VERSION ""

NS_ :

BS_:

BU_: AMS_Impeller FCU DMI Logger MCU RCU AMS
VAL_TABLE_ MCU_Control_Drive_Mode 3 "Torque Vectoring" 2 "Slip Control" 1 "Torque Limiting" 0 "Throttle Curve" ;
VAL_TABLE_ MCU_Inverter_State_VT 3 "Error" 2 "Active" 1 "Ready" 0 "Init" ;
VAL_TABLE_ Fuse_Set_Enable 2 "Enable E-Fuse" 1 "Disable E-Fuse" 0 "No Change" ;
VAL_TABLE_ Fuse_Fault 1 "E-Fuse no fault" 0 "E-Fuse has fault" ;
VAL_TABLE_ Fuse_Enable 1 "E-Fuse enabled" 0 "E-Fuse disabled" ;

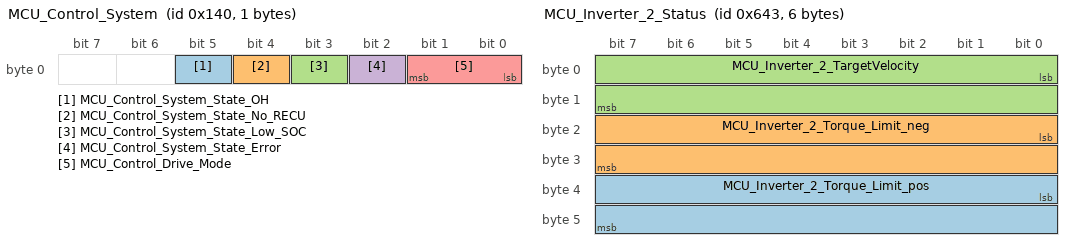
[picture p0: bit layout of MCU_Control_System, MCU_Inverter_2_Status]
BO_ 320 MCU_Control_System: 1 MCU
 SG_ MCU_Control_System_State_OH : 5|1@1+ (1,0) [0|1] "" Vector__XXX
 SG_ MCU_Control_System_State_No_RECU : 4|1@1+ (1,0) [0|1] "" Vector__XXX
 SG_ MCU_Control_System_State_Low_SOC : 3|1@1+ (1,0) [0|1] "" Vector__XXX
 SG_ MCU_Control_System_State_Error : 2|1@1+ (1,0) [0|1] "" Vector__XXX
 SG_ MCU_Control_Drive_Mode : 0|2@1+ (1,0) [0|3] "" Vector__XXX

BO_ 1603 MCU_Inverter_2_Status: 6 MCU
 SG_ MCU_Inverter_2_Torque_Limit_pos : 32|16@1+ (0.1,0) [0|1000] "%" Vector__XXX
 SG_ MCU_Inverter_2_Torque_Limit_neg : 16|16@1+ (0.1,0) [0|1000] "%" Vector__XXX
 SG_ MCU_Inverter_2_TargetVelocity : 0|16@1+ (1,0) [0|65535] "rpm" Vector__XXX

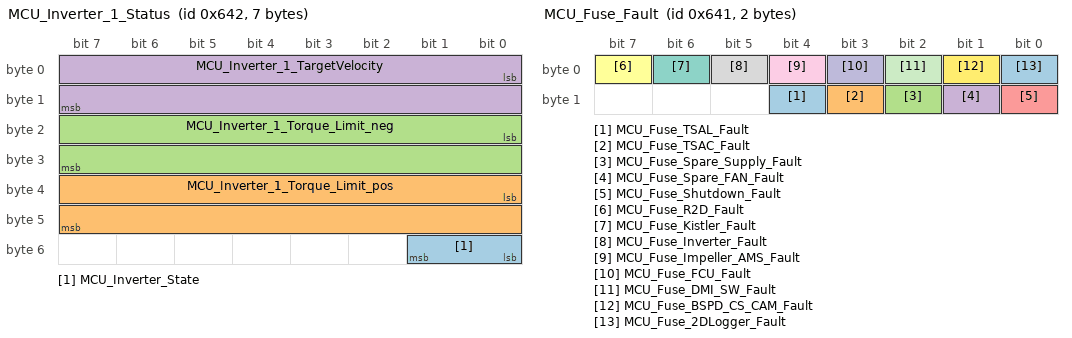
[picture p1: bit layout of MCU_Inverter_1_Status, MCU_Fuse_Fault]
BO_ 1602 MCU_Inverter_1_Status: 7 MCU
 SG_ MCU_Inverter_State : 48|2@1+ (1,0) [0|3] "" Vector__XXX
 SG_ MCU_Inverter_1_Torque_Limit_pos : 32|16@1+ (0.1,0) [0|1000] "%" Vector__XXX
 SG_ MCU_Inverter_1_Torque_Limit_neg : 16|16@1+ (0.1,0) [0|1000] "%" Vector__XXX
 SG_ MCU_Inverter_1_TargetVelocity : 0|16@1+ (1,0) [0|65535] "rpm" Vector__XXX

BO_ 1601 MCU_Fuse_Fault: 2 MCU
 SG_ MCU_Fuse_TSAL_Fault : 12|1@1+ (1,0) [0|1] "" Vector__XXX
 SG_ MCU_Fuse_TSAC_Fault : 11|1@1+ (1,0) [0|1] "" Vector__XXX
 SG_ MCU_Fuse_Spare_Supply_Fault : 10|1@1+ (1,0) [0|1] "" Vector__XXX
 SG_ MCU_Fuse_Spare_FAN_Fault : 9|1@1+ (1,0) [0|1] "" Vector__XXX
 SG_ MCU_Fuse_Shutdown_Fault : 8|1@1+ (1,0) [0|1] "" Vector__XXX
 SG_ MCU_Fuse_R2D_Fault : 7|1@1+ (1,0) [0|1] "" Vector__XXX
 SG_ MCU_Fuse_Kistler_Fault : 6|1@1+ (1,0) [0|1] "" Vector__XXX
 SG_ MCU_Fuse_Inverter_Fault : 5|1@1+ (1,0) [0|1] "" Vector__XXX
 SG_ MCU_Fuse_Impeller_AMS_Fault : 4|1@1+ (1,0) [0|1] "" Vector__XXX
 SG_ MCU_Fuse_FCU_Fault : 3|1@1+ (1,0) [0|1] "" Vector__XXX
 SG_ MCU_Fuse_DMI_SW_Fault : 2|1@1+ (1,0) [0|1] "" Vector__XXX
 SG_ MCU_Fuse_BSPD_CS_CAM_Fault : 1|1@1+ (1,0) [0|1] "" Vector__XXX
 SG_ MCU_Fuse_2DLogger_Fault : 0|1@1+ (1,0) [0|1] "" Vector__XXX

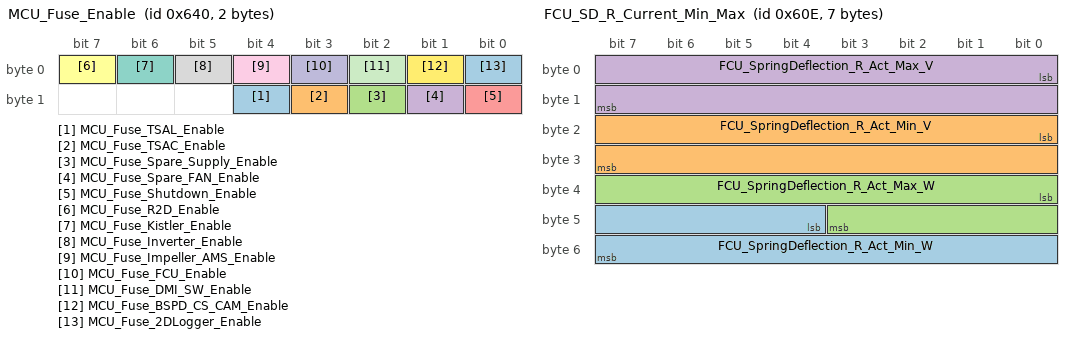
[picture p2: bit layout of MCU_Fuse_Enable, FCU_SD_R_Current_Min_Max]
BO_ 1600 MCU_Fuse_Enable: 2 MCU
 SG_ MCU_Fuse_TSAL_Enable : 12|1@1+ (1,0) [0|1] "" Vector__XXX
 SG_ MCU_Fuse_TSAC_Enable : 11|1@1+ (1,0) [0|1] "" Vector__XXX
 SG_ MCU_Fuse_Spare_Supply_Enable : 10|1@1+ (1,0) [0|1] "" Vector__XXX
 SG_ MCU_Fuse_Spare_FAN_Enable : 9|1@1+ (1,0) [0|1] "" Vector__XXX
 SG_ MCU_Fuse_Shutdown_Enable : 8|1@1+ (1,0) [0|1] "" Vector__XXX
 SG_ MCU_Fuse_R2D_Enable : 7|1@1+ (1,0) [0|1] "" Vector__XXX
 SG_ MCU_Fuse_Kistler_Enable : 6|1@1+ (1,0) [0|1] "" Vector__XXX
 SG_ MCU_Fuse_Inverter_Enable : 5|1@1+ (1,0) [0|1] "" Vector__XXX
 SG_ MCU_Fuse_Impeller_AMS_Enable : 4|1@1+ (1,0) [0|1] "" Vector__XXX
 SG_ MCU_Fuse_FCU_Enable : 3|1@1+ (1,0) [0|1] "" Vector__XXX
 SG_ MCU_Fuse_DMI_SW_Enable : 2|1@1+ (1,0) [0|1] "" Vector__XXX
 SG_ MCU_Fuse_BSPD_CS_CAM_Enable : 1|1@1+ (1,0) [0|1] "" Vector__XXX
 SG_ MCU_Fuse_2DLogger_Enable : 0|1@1+ (1,0) [0|1] "" Vector__XXX

BO_ 1550 FCU_SD_R_Current_Min_Max: 7 FCU
 SG_ FCU_SpringDeflection_R_Act_Min_W : 44|12@1+ (0.02,0) [0|81.9] "" Vector__XXX
 SG_ FCU_SpringDeflection_R_Act_Min_V : 16|16@1+ (0.001,0) [0|5] "V" Vector__XXX
 SG_ FCU_SpringDeflection_R_Act_Max_W : 32|12@1+ (0.02,0) [0|81.9] "" Vector__XXX
 SG_ FCU_SpringDeflection_R_Act_Max_V : 0|16@1+ (0.001,0) [0|5] "V" Vector__XXX

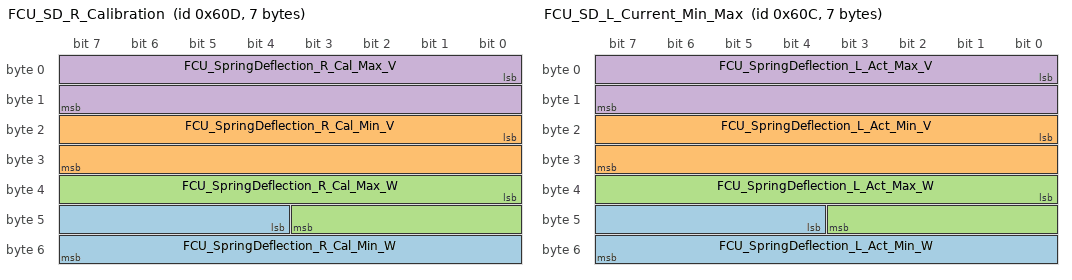
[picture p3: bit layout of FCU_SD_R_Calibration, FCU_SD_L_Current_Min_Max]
BO_ 1549 FCU_SD_R_Calibration: 7 Logger
 SG_ FCU_SpringDeflection_R_Cal_Min_W : 44|12@1+ (0.02,0) [0|81.9] ""  FCU
 SG_ FCU_SpringDeflection_R_Cal_Min_V : 16|16@1+ (0.001,0) [0|5] "V"  FCU
 SG_ FCU_SpringDeflection_R_Cal_Max_W : 32|12@1+ (0.02,0) [0|81.9] ""  FCU
 SG_ FCU_SpringDeflection_R_Cal_Max_V : 0|16@1+ (0.001,0) [0|5] "V"  FCU

BO_ 1548 FCU_SD_L_Current_Min_Max: 7 FCU
 SG_ FCU_SpringDeflection_L_Act_Min_W : 44|12@1+ (0.02,0) [0|81.9] "" Vector__XXX
 SG_ FCU_SpringDeflection_L_Act_Min_V : 16|16@1+ (0.001,0) [0|5] "V" Vector__XXX
 SG_ FCU_SpringDeflection_L_Act_Max_W : 32|12@1+ (0.02,0) [0|81.9] "" Vector__XXX
 SG_ FCU_SpringDeflection_L_Act_Max_V : 0|16@1+ (0.001,0) [0|5] "V" Vector__XXX

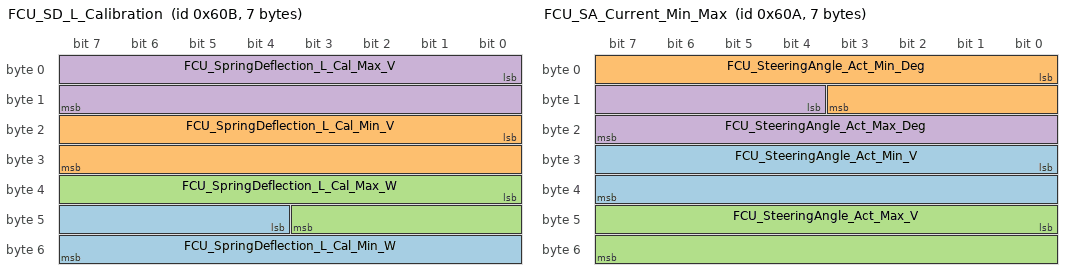
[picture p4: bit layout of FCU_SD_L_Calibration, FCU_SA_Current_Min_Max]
BO_ 1547 FCU_SD_L_Calibration: 7 Logger
 SG_ FCU_SpringDeflection_L_Cal_Min_W : 44|12@1+ (0.02,0) [0|81.9] ""  FCU
 SG_ FCU_SpringDeflection_L_Cal_Min_V : 16|16@1+ (0.001,0) [0|5] "V"  FCU
 SG_ FCU_SpringDeflection_L_Cal_Max_W : 32|12@1+ (0.02,0) [0|81.9] ""  FCU
 SG_ FCU_SpringDeflection_L_Cal_Max_V : 0|16@1+ (0.001,0) [0|5] "V"  FCU

BO_ 1546 FCU_SA_Current_Min_Max: 7 FCU
 SG_ FCU_SteeringAngle_Act_Min_V : 24|16@1+ (0.001,0) [0|5] "V" Vector__XXX
 SG_ FCU_SteeringAngle_Act_Min_Deg : 0|12@1- (0.15,0) [-307.2|307.05] "" Vector__XXX
 SG_ FCU_SteeringAngle_Act_Max_V : 40|16@1+ (0.001,0) [0|5] "V" Vector__XXX
 SG_ FCU_SteeringAngle_Act_Max_Deg : 12|12@1- (0.15,0) [-307.2|307.05] "" Vector__XXX

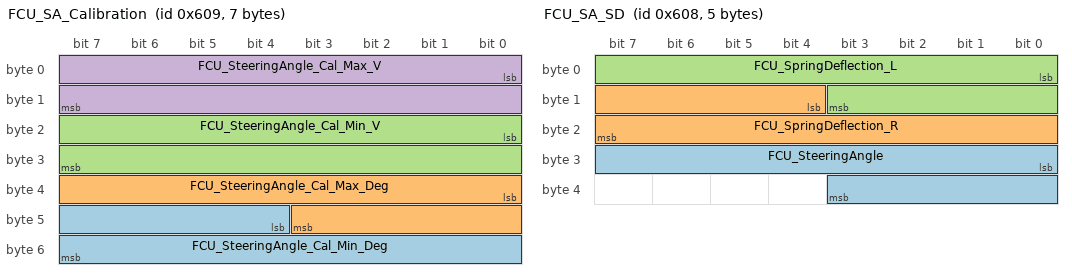
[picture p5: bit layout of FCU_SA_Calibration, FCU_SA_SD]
BO_ 1545 FCU_SA_Calibration: 7 Logger
 SG_ FCU_SteeringAngle_Cal_Min_Deg : 44|12@1- (0.15,0) [-307.2|307.05] ""  FCU
 SG_ FCU_SteeringAngle_Cal_Max_Deg : 32|12@1- (0.15,0) [-307.2|307.05] ""  FCU
 SG_ FCU_SteeringAngle_Cal_Min_V : 16|16@1+ (0.001,0) [0|5] "V"  FCU
 SG_ FCU_SteeringAngle_Cal_Max_V : 0|16@1+ (0.001,0) [0|5] "V"  FCU

BO_ 1544 FCU_SA_SD: 5 FCU
 SG_ FCU_SteeringAngle : 24|12@1- (0.15,0) [-307.2|307.05] "" Vector__XXX
 SG_ FCU_SpringDeflection_R : 12|12@1+ (0.02,0) [0|81.9] "" Vector__XXX
 SG_ FCU_SpringDeflection_L : 0|12@1+ (0.02,0) [0|81.9] "" Vector__XXX

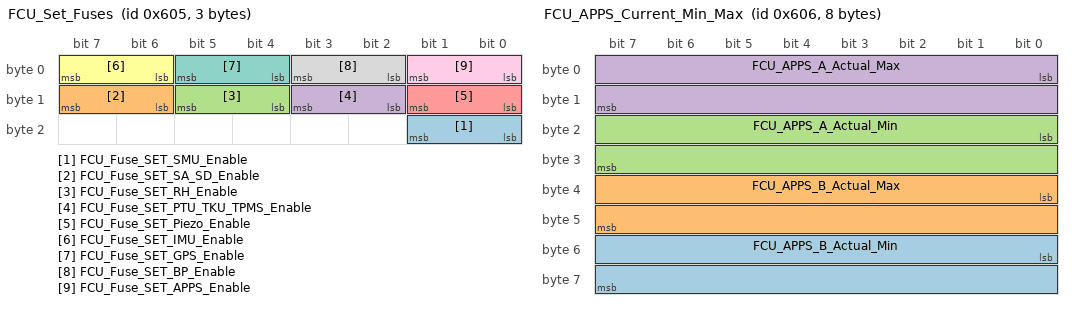
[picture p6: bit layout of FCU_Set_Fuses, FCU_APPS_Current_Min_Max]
BO_ 1541 FCU_Set_Fuses: 3 FCU
 SG_ FCU_Fuse_SET_SMU_Enable : 16|2@1+ (1,-1) [-1|1] "" Vector__XXX
 SG_ FCU_Fuse_SET_SA_SD_Enable : 14|2@1+ (1,-1) [-1|1] "" Vector__XXX
 SG_ FCU_Fuse_SET_RH_Enable : 12|2@1+ (1,-1) [-1|1] "" Vector__XXX
 SG_ FCU_Fuse_SET_PTU_TKU_TPMS_Enable : 10|2@1+ (1,-1) [-1|1] "" Vector__XXX
 SG_ FCU_Fuse_SET_Piezo_Enable : 8|2@1+ (1,-1) [-1|1] "" Vector__XXX
 SG_ FCU_Fuse_SET_IMU_Enable : 6|2@1+ (1,-1) [-1|1] "" Vector__XXX
 SG_ FCU_Fuse_SET_GPS_Enable : 4|2@1+ (1,-1) [-1|1] "" Vector__XXX
 SG_ FCU_Fuse_SET_BP_Enable : 2|2@1+ (1,-1) [-1|1] "" Vector__XXX
 SG_ FCU_Fuse_SET_APPS_Enable : 0|2@1+ (1,-1) [-1|1] "" Vector__XXX

BO_ 1542 FCU_APPS_Current_Min_Max: 8 FCU
 SG_ FCU_APPS_B_Actual_Min : 48|16@1+ (0.001,0) [0|5] "V" Vector__XXX
 SG_ FCU_APPS_B_Actual_Max : 32|16@1+ (0.001,0) [0|5] "V" Vector__XXX
 SG_ FCU_APPS_A_Actual_Min : 16|16@1+ (0.001,0) [0|5] "V" Vector__XXX
 SG_ FCU_APPS_A_Actual_Max : 0|16@1+ (0.001,0) [0|5] "V" Vector__XXX

BO_ 1540 FCU_State: 1 FCU
 SG_ FCU_Alive : 0|8@1+ (1,0) [0|255] "" Vector__XXX

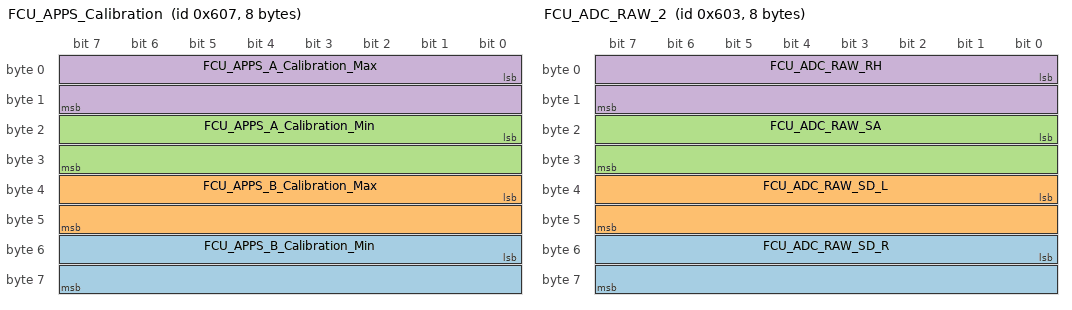
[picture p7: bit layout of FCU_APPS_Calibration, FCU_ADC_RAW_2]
BO_ 1543 FCU_APPS_Calibration: 8 Logger
 SG_ FCU_APPS_B_Calibration_Min : 48|16@1+ (0.001,0) [0|5] "V"  FCU
 SG_ FCU_APPS_B_Calibration_Max : 32|16@1+ (0.001,0) [0|5] "V"  FCU
 SG_ FCU_APPS_A_Calibration_Min : 16|16@1+ (0.001,0) [0|5] "V"  FCU
 SG_ FCU_APPS_A_Calibration_Max : 0|16@1+ (0.001,0) [0|5] "V"  FCU

BO_ 257 FCU_BP: 4 FCU
 SG_ FCU_BP_R : 16|12@1+ (0.1,0) [0|200] "bar" Vector__XXX
 SG_ FCU_BP_F : 0|12@1+ (0.1,0) [0|200] "bar" Vector__XXX

BO_ 256 FCU_APPS: 4 FCU
 SG_ FCU_APPS_B : 16|10@1+ (0.1,0) [0|100] "%" Vector__XXX
 SG_ FCU_APPS_A : 0|10@1+ (0.1,0) [0|100] "%" Vector__XXX

BO_ 1539 FCU_ADC_RAW_2: 8 FCU
 SG_ FCU_ADC_RAW_SD_R : 48|16@1+ (0.001,0) [0|5] "V" Vector__XXX
 SG_ FCU_ADC_RAW_SD_L : 32|16@1+ (0.001,0) [0|5] "V" Vector__XXX
 SG_ FCU_ADC_RAW_SA : 16|16@1+ (0.001,0) [0|5] "V" Vector__XXX
 SG_ FCU_ADC_RAW_RH : 0|16@1+ (0.001,0) [0|5] "V" Vector__XXX

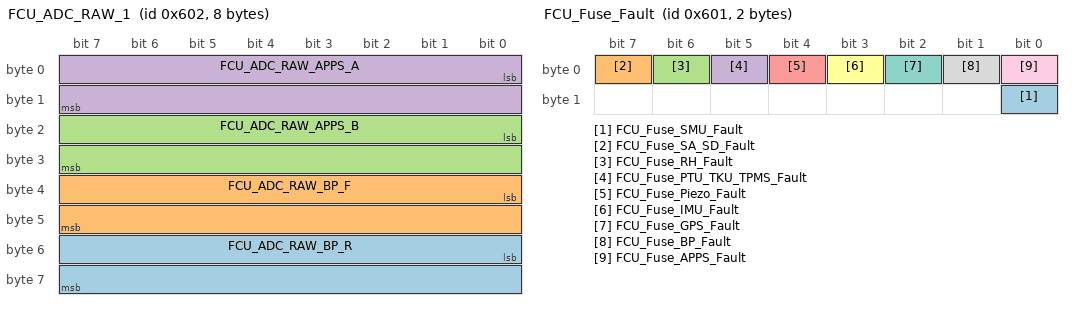
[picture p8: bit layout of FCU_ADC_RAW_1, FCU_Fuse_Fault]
BO_ 1538 FCU_ADC_RAW_1: 8 FCU
 SG_ FCU_ADC_RAW_BP_R : 48|16@1+ (0.001,0) [0|5] "V" Vector__XXX
 SG_ FCU_ADC_RAW_BP_F : 32|16@1+ (0.001,0) [0|5] "V" Vector__XXX
 SG_ FCU_ADC_RAW_APPS_B : 16|16@1+ (0.001,0) [0|5] "V" Vector__XXX
 SG_ FCU_ADC_RAW_APPS_A : 0|16@1+ (0.001,0) [0|5] "V" Vector__XXX

BO_ 1537 FCU_Fuse_Fault: 2 FCU
 SG_ FCU_Fuse_SMU_Fault : 8|1@1+ (1,0) [0|1] "" Vector__XXX
 SG_ FCU_Fuse_SA_SD_Fault : 7|1@1+ (1,0) [0|1] "" Vector__XXX
 SG_ FCU_Fuse_RH_Fault : 6|1@1+ (1,0) [0|1] "" Vector__XXX
 SG_ FCU_Fuse_PTU_TKU_TPMS_Fault : 5|1@1+ (1,0) [0|1] "" Vector__XXX
 SG_ FCU_Fuse_Piezo_Fault : 4|1@1+ (1,0) [0|1] "" Vector__XXX
 SG_ FCU_Fuse_IMU_Fault : 3|1@1+ (1,0) [0|1] "" Vector__XXX
 SG_ FCU_Fuse_GPS_Fault : 2|1@1+ (1,0) [0|1] "" Vector__XXX
 SG_ FCU_Fuse_BP_Fault : 1|1@1+ (1,0) [0|1] "" Vector__XXX
 SG_ FCU_Fuse_APPS_Fault : 0|1@1+ (1,0) [0|1] "" Vector__XXX

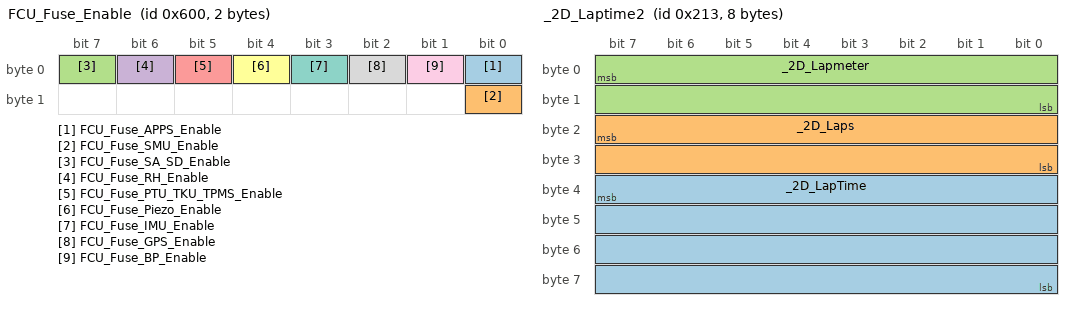
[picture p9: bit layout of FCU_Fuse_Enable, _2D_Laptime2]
BO_ 1536 FCU_Fuse_Enable: 2 FCU
 SG_ FCU_Fuse_APPS_Enable : 0|1@1+ (1,0) [0|1] "" Vector__XXX
 SG_ FCU_Fuse_SMU_Enable : 8|1@1+ (1,0) [0|1] "" Vector__XXX
 SG_ FCU_Fuse_SA_SD_Enable : 7|1@1+ (1,0) [0|1] "" Vector__XXX
 SG_ FCU_Fuse_RH_Enable : 6|1@1+ (1,0) [0|1] "" Vector__XXX
 SG_ FCU_Fuse_PTU_TKU_TPMS_Enable : 5|1@1+ (1,0) [0|1] "" Vector__XXX
 SG_ FCU_Fuse_Piezo_Enable : 4|1@1+ (1,0) [0|1] "" Vector__XXX
 SG_ FCU_Fuse_IMU_Enable : 3|1@1+ (1,0) [0|1] "" Vector__XXX
 SG_ FCU_Fuse_GPS_Enable : 2|1@1+ (1,0) [0|1] "" Vector__XXX
 SG_ FCU_Fuse_BP_Enable : 1|1@1+ (1,0) [0|1] "" Vector__XXX

BO_ 531 _2D_Laptime2: 8 Logger
 SG_ _2D_LapTime : 39|32@0+ (0.001,0) [0|4294967.295] "s" Vector__XXX
 SG_ _2D_Laps : 23|16@0+ (1,0) [0|65535] "#" Vector__XXX
 SG_ _2D_Lapmeter : 7|16@0+ (0.5,0) [0|32767.5] "m" Vector__XXX

BO_ 514 _2D_Laptime1: 4 Logger
 SG_ _2D_deltaToBest : 23|16@0- (0.001,0) [-32.768|32.767] "s" Vector__XXX
 SG_ _2D_BestLap : 7|16@0+ (0.001,0) [0|65.535] "s" Vector__XXX

CM_ SG_ 320 MCU_Control_System_State_OH "Overheat";
CM_ SG_ 320 MCU_Control_System_State_Error "Overheat";
CM_ SG_ 320 MCU_Control_Drive_Mode "Overheat";
CM_ SG_ 1550 FCU_SpringDeflection_R_Act_Min_V "Displays the current set max value for APPS";
CM_ SG_ 1550 FCU_SpringDeflection_R_Act_Max_V "Displays the current set max value for APPS";
CM_ SG_ 1549 FCU_SpringDeflection_R_Cal_Min_V "Displays the current set max value for APPS";
CM_ SG_ 1549 FCU_SpringDeflection_R_Cal_Max_V "Displays the current set max value for APPS";
CM_ SG_ 1548 FCU_SpringDeflection_L_Act_Min_V "Displays the current set max value for APPS";
CM_ SG_ 1548 FCU_SpringDeflection_L_Act_Max_V "Displays the current set max value for APPS";
CM_ SG_ 1547 FCU_SpringDeflection_L_Cal_Min_V "Displays the current set max value for APPS";
CM_ SG_ 1547 FCU_SpringDeflection_L_Cal_Max_V "Displays the current set max value for APPS";
CM_ SG_ 1546 FCU_SteeringAngle_Act_Min_V "Displays the current set max value for APPS";
CM_ SG_ 1546 FCU_SteeringAngle_Act_Max_V "Displays the current set max value for APPS";
CM_ SG_ 1545 FCU_SteeringAngle_Cal_Min_V "Displays the current set max value for APPS";
CM_ SG_ 1545 FCU_SteeringAngle_Cal_Max_V "Displays the current set max value for APPS";
CM_ BO_ 1542 "Currently active min and max values";
CM_ SG_ 1542 FCU_APPS_B_Actual_Min "Displays the current set min value for APPS";
CM_ SG_ 1542 FCU_APPS_B_Actual_Max "Displays the current set max value for APPS";
CM_ SG_ 1542 FCU_APPS_A_Actual_Min "Displays the current set min value for APPS";
CM_ SG_ 1542 FCU_APPS_A_Actual_Max "Displays the current set max value for APPS";
BA_DEF_ SG_  "GenSigStartValue" FLOAT 0 100000000000;
BA_DEF_ SG_  "GenSigSendType" ENUM  "Cyclic","OnWrite","OnWriteWithRepetition","OnChange","OnChangeWithRepetition","IfActive","IfActiveWithRepetition","NoSigSendType","NotUsed","NotUsed","NotUsed","NotUsed","NotUsed";
BA_DEF_ BO_  "GenMsgILSupport" ENUM  "No","Yes";
BA_DEF_ BO_  "GenMsgSendType2" ENUM  "Zyklisch","Ereignisgesteuert","dummy","Auf Anfrage";
BA_DEF_ BO_  "GenMsgFastOnStart" INT 10 500;
BA_DEF_ BO_  "GenMsgCycleTimeActive" INT 1 100;
BA_DEF_ BO_  "VFrameFormat" ENUM  "StandardCAN","ExtendedCAN","reserved","reserved","reserved","reserved","reserved","reserved","reserved","reserved","reserved","reserved","reserved","reserved","StandardCAN_FD","ExtendedCAN_FD";
BA_DEF_ BO_  "GenMsgSendType" ENUM  "Cyclic","NotUsed","NotUsed","NotUsed","NotUsed","NotUsed","NotUsed","IfActive","NoMsgSendType","NotUsed","vector_leerstring";
BA_DEF_ BO_  "GenMsgCycleTime" INT 0 50000;
BA_DEF_  "BusType" STRING ;
BA_DEF_DEF_  "GenSigStartValue" 0;
BA_DEF_DEF_  "GenSigSendType" "Cyclic";
BA_DEF_DEF_  "GenMsgILSupport" "Yes";
BA_DEF_DEF_  "GenMsgSendType2" "Zyklisch";
BA_DEF_DEF_  "GenMsgFastOnStart" 10;
BA_DEF_DEF_  "GenMsgCycleTimeActive" 10;
BA_DEF_DEF_  "VFrameFormat" "ExtendedCAN_FD";
BA_DEF_DEF_  "GenMsgSendType" "NoMsgSendType";
BA_DEF_DEF_  "GenMsgCycleTime" 0;
BA_DEF_DEF_  "BusType" "CAN";
BA_ "VFrameFormat" BO_ 320 0;
BA_ "VFrameFormat" BO_ 1603 0;
BA_ "VFrameFormat" BO_ 1602 0;
BA_ "VFrameFormat" BO_ 1601 0;
BA_ "VFrameFormat" BO_ 1600 0;
BA_ "VFrameFormat" BO_ 1550 0;
BA_ "GenMsgCycleTime" BO_ 1550 1000;
BA_ "GenMsgSendType2" BO_ 1549 1;
BA_ "VFrameFormat" BO_ 1549 0;
BA_ "GenMsgSendType" BO_ 1549 1;
BA_ "VFrameFormat" BO_ 1548 0;
BA_ "GenMsgCycleTime" BO_ 1548 1000;
BA_ "VFrameFormat" BO_ 1547 0;
BA_ "VFrameFormat" BO_ 1546 0;
BA_ "GenMsgCycleTime" BO_ 1546 1000;
BA_ "GenMsgSendType2" BO_ 1545 1;
BA_ "VFrameFormat" BO_ 1545 0;
BA_ "GenMsgSendType" BO_ 1545 1;
BA_ "VFrameFormat" BO_ 1544 0;
BA_ "VFrameFormat" BO_ 1541 0;
BA_ "VFrameFormat" BO_ 1542 0;
BA_ "GenMsgCycleTime" BO_ 1542 1000;
BA_ "VFrameFormat" BO_ 1540 0;
BA_ "GenMsgSendType2" BO_ 1543 1;
BA_ "VFrameFormat" BO_ 1543 0;
BA_ "GenMsgSendType" BO_ 1543 1;
BA_ "VFrameFormat" BO_ 257 0;
BA_ "GenMsgSendType" BO_ 257 0;
BA_ "GenMsgCycleTime" BO_ 257 10;
BA_ "VFrameFormat" BO_ 256 0;
BA_ "GenMsgCycleTime" BO_ 256 10;
BA_ "VFrameFormat" BO_ 1539 0;
BA_ "VFrameFormat" BO_ 1538 0;
BA_ "VFrameFormat" BO_ 1537 0;
BA_ "VFrameFormat" BO_ 1536 0;
BA_ "VFrameFormat" BO_ 531 0;
BA_ "VFrameFormat" BO_ 514 0;
BA_ "GenSigStartValue" SG_ 1541 FCU_Fuse_SET_SMU_Enable 1;
BA_ "GenSigStartValue" SG_ 1541 FCU_Fuse_SET_SA_SD_Enable 1;
BA_ "GenSigStartValue" SG_ 1541 FCU_Fuse_SET_RH_Enable 1;
BA_ "GenSigStartValue" SG_ 1541 FCU_Fuse_SET_PTU_TKU_TPMS_Enable 1;
BA_ "GenSigStartValue" SG_ 1541 FCU_Fuse_SET_Piezo_Enable 1;
BA_ "GenSigStartValue" SG_ 1541 FCU_Fuse_SET_IMU_Enable 1;
BA_ "GenSigStartValue" SG_ 1541 FCU_Fuse_SET_GPS_Enable 1;
BA_ "GenSigStartValue" SG_ 1541 FCU_Fuse_SET_BP_Enable 1;
BA_ "GenSigStartValue" SG_ 1541 FCU_Fuse_SET_APPS_Enable 1;
VAL_ 320 MCU_Control_Drive_Mode 3 "Torque Vectoring" 2 "Slip Control" 1 "Torque Limiting" 0 "Throttle Curve" ;
VAL_ 1602 MCU_Inverter_State 3 "Error" 2 "Active" 1 "Ready" 0 "Init" ;
VAL_ 1601 MCU_Fuse_TSAL_Fault 1 "E-Fuse no fault" 0 "E-Fuse has fault" ;
VAL_ 1601 MCU_Fuse_TSAC_Fault 1 "E-Fuse no fault" 0 "E-Fuse has fault" ;
VAL_ 1601 MCU_Fuse_Spare_Supply_Fault 1 "E-Fuse no fault" 0 "E-Fuse has fault" ;
VAL_ 1601 MCU_Fuse_Spare_FAN_Fault 1 "E-Fuse no fault" 0 "E-Fuse has fault" ;
VAL_ 1601 MCU_Fuse_Shutdown_Fault 1 "E-Fuse no fault" 0 "E-Fuse has fault" ;
VAL_ 1601 MCU_Fuse_R2D_Fault 1 "E-Fuse no fault" 0 "E-Fuse has fault" ;
VAL_ 1601 MCU_Fuse_Kistler_Fault 1 "E-Fuse no fault" 0 "E-Fuse has fault" ;
VAL_ 1601 MCU_Fuse_Inverter_Fault 1 "E-Fuse no fault" 0 "E-Fuse has fault" ;
VAL_ 1601 MCU_Fuse_Impeller_AMS_Fault 1 "E-Fuse no fault" 0 "E-Fuse has fault" ;
VAL_ 1601 MCU_Fuse_FCU_Fault 1 "E-Fuse no fault" 0 "E-Fuse has fault" ;
VAL_ 1601 MCU_Fuse_DMI_SW_Fault 1 "E-Fuse no fault" 0 "E-Fuse has fault" ;
VAL_ 1601 MCU_Fuse_BSPD_CS_CAM_Fault 1 "E-Fuse no fault" 0 "E-Fuse has fault" ;
VAL_ 1601 MCU_Fuse_2DLogger_Fault 1 "E-Fuse no fault" 0 "E-Fuse has fault" ;
VAL_ 1600 MCU_Fuse_TSAL_Enable 1 "E-Fuse enabled" 0 "E-Fuse disabled" ;
VAL_ 1600 MCU_Fuse_TSAC_Enable 1 "E-Fuse enabled" 0 "E-Fuse disabled" ;
VAL_ 1600 MCU_Fuse_Spare_Supply_Enable 1 "E-Fuse enabled" 0 "E-Fuse disabled" ;
VAL_ 1600 MCU_Fuse_Spare_FAN_Enable 1 "E-Fuse enabled" 0 "E-Fuse disabled" ;
VAL_ 1600 MCU_Fuse_Shutdown_Enable 1 "E-Fuse enabled" 0 "E-Fuse disabled" ;
VAL_ 1600 MCU_Fuse_R2D_Enable 1 "E-Fuse enabled" 0 "E-Fuse disabled" ;
VAL_ 1600 MCU_Fuse_Kistler_Enable 1 "E-Fuse enabled" 0 "E-Fuse disabled" ;
VAL_ 1600 MCU_Fuse_Inverter_Enable 1 "E-Fuse enabled" 0 "E-Fuse disabled" ;
VAL_ 1600 MCU_Fuse_Impeller_AMS_Enable 1 "E-Fuse enabled" 0 "E-Fuse disabled" ;
VAL_ 1600 MCU_Fuse_FCU_Enable 1 "E-Fuse enabled" 0 "E-Fuse disabled" ;
VAL_ 1600 MCU_Fuse_DMI_SW_Enable 1 "E-Fuse enabled" 0 "E-Fuse disabled" ;
VAL_ 1600 MCU_Fuse_BSPD_CS_CAM_Enable 1 "E-Fuse enabled" 0 "E-Fuse disabled" ;
VAL_ 1600 MCU_Fuse_2DLogger_Enable 1 "E-Fuse enabled" 0 "E-Fuse disabled" ;
VAL_ 1541 FCU_Fuse_SET_SMU_Enable 2 "Enable E-Fuse" 1 "Disable E-Fuse" 0 "No Change" ;
VAL_ 1541 FCU_Fuse_SET_SA_SD_Enable 2 "Enable E-Fuse" 1 "Disable E-Fuse" 0 "No Change" ;
VAL_ 1541 FCU_Fuse_SET_RH_Enable 2 "Enable E-Fuse" 1 "Disable E-Fuse" 0 "No Change" ;
VAL_ 1541 FCU_Fuse_SET_PTU_TKU_TPMS_Enable 2 "Enable E-Fuse" 1 "Disable E-Fuse" 0 "No Change" ;
VAL_ 1541 FCU_Fuse_SET_Piezo_Enable 2 "Enable E-Fuse" 1 "Disable E-Fuse" 0 "No Change" ;
VAL_ 1541 FCU_Fuse_SET_IMU_Enable 2 "Enable E-Fuse" 1 "Disable E-Fuse" 0 "No Change" ;
VAL_ 1541 FCU_Fuse_SET_GPS_Enable 2 "Enable E-Fuse" 1 "Disable E-Fuse" 0 "No Change" ;
VAL_ 1541 FCU_Fuse_SET_BP_Enable 2 "Enable E-Fuse" 1 "Disable E-Fuse" 0 "No Change" ;
VAL_ 1541 FCU_Fuse_SET_APPS_Enable 2 "Enable E-Fuse" 1 "Disable E-Fuse" 0 "No Change" ;
VAL_ 1537 FCU_Fuse_SMU_Fault 1 "E-Fuse no fault" 0 "E-Fuse has fault" ;
VAL_ 1537 FCU_Fuse_SA_SD_Fault 1 "E-Fuse no fault" 0 "E-Fuse has fault" ;
VAL_ 1537 FCU_Fuse_RH_Fault 1 "E-Fuse no fault" 0 "E-Fuse has fault" ;
VAL_ 1537 FCU_Fuse_PTU_TKU_TPMS_Fault 1 "E-Fuse no fault" 0 "E-Fuse has fault" ;
VAL_ 1537 FCU_Fuse_Piezo_Fault 1 "E-Fuse no fault" 0 "E-Fuse has fault" ;
VAL_ 1537 FCU_Fuse_IMU_Fault 1 "E-Fuse no fault" 0 "E-Fuse has fault" ;
VAL_ 1537 FCU_Fuse_GPS_Fault 1 "E-Fuse no fault" 0 "E-Fuse has fault" ;
VAL_ 1537 FCU_Fuse_BP_Fault 1 "E-Fuse no fault" 0 "E-Fuse has fault" ;
VAL_ 1537 FCU_Fuse_APPS_Fault 1 "E-Fuse no fault" 0 "E-Fuse has fault" ;
VAL_ 1536 FCU_Fuse_APPS_Enable 1 "E-Fuse enabled" 0 "E-Fuse disabled" ;
VAL_ 1536 FCU_Fuse_SMU_Enable 1 "E-Fuse enabled" 0 "E-Fuse disabled" ;
VAL_ 1536 FCU_Fuse_SA_SD_Enable 1 "E-Fuse enabled" 0 "E-Fuse disabled" ;
VAL_ 1536 FCU_Fuse_RH_Enable 1 "E-Fuse enabled" 0 "E-Fuse disabled" ;
VAL_ 1536 FCU_Fuse_PTU_TKU_TPMS_Enable 1 "E-Fuse enabled" 0 "E-Fuse disabled" ;
VAL_ 1536 FCU_Fuse_Piezo_Enable 1 "E-Fuse enabled" 0 "E-Fuse disabled" ;
VAL_ 1536 FCU_Fuse_IMU_Enable 1 "E-Fuse enabled" 0 "E-Fuse disabled" ;
VAL_ 1536 FCU_Fuse_GPS_Enable 1 "E-Fuse enabled" 0 "E-Fuse disabled" ;
VAL_ 1536 FCU_Fuse_BP_Enable 1 "E-Fuse enabled" 0 "E-Fuse disabled" ;
